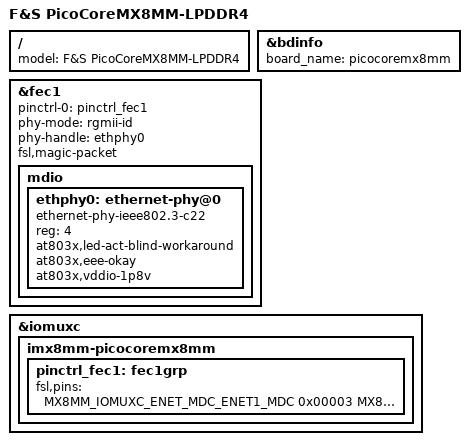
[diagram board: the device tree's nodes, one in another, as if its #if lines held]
/*
 * Copyright (C) 2019 F&S Elektronik Systeme GmbH
 *
 * This program is free software; you can redistribute it and/or modify
 * it under the terms of the GNU General Public License version 2 as
 * published by the Free Software Foundation.
 */

/dts-v1/;

/* Set board revision as 3-digit number, e.g. 110 for board rev. 1.10 */
#define CONFIG_PICOCOREMX8MM_BOARD_REVISION	130
/* Set baseboard revision as 3-digit number, e.g. 110 for board rev. 1.10 */
#define CONFIG_PICOCOREBBDSI_BOARD_REVISION	130

/* Activate this if you want to use the Cortex-M4 core */
//#define SUPPORT_M4

/* Display device-trees enables MIPI DSI */
/* MIPI DSI */
//#define CONFIG_PICOCOREMX8MM_MIPI_DSI

/*### UBoot deactivates on of the two boot medium NAND/eMMC */
/* On-board NAND */
#define CONFIG_PICOCOREMX8MM_NAND

/* On-board eMMC */
#define CONFIG_PICOCOREMX8MM_EMMC

/* Network */
#define CONFIG_PICOCOREMX8MM_ETH

/* WLAN/BLUETOOTH; either WLAN-only or combined WLAN/Bluetooth chip */
#define CONFIG_PICOCOREMX8MM_WLAN

/* USB */
#define CONFIG_PICOCOREMX8MM_USB_OTG1
#define CONFIG_PICOCOREMX8MM_USB_HOST
#define CONFIG_PICOCOREMX8MM_USB_OTG1_USBC
/* USB Type-C ALERT signal is available on J2_77 on BBDSI baseboard since
   Revision 1.40. Otherwise use polling with ~100ms */
#define CONFIG_PICOCOREMX8MM_USB_OTG1_USBC_ALERT

/* PCIe */
#define CONFIG_PICOCOREMX8MM_PCIE

/* I2C */
#define CONFIG_PICOCOREMX8MM_I2C_A
#define CONFIG_PICOCOREMX8MM_I2C_B
#define CONFIG_PICOCOREMX8MM_I2C_C
#define CONFIG_PICOCOREMX8MM_I2C_D

/* PWM and backlight brightness */
#define CONFIG_PICOCOREMX8MM_PWM_A
#define CONFIG_PICOCOREMX8MM_BL_CTRL

/* UART_A - UART1 */
#define CONFIG_PICOCOREMX8MM_UART_A
#define CONFIG_PICOCOREMX8MM_UART_A_RTSCTS

/* UART_B - UART2 */
#define CONFIG_PICOCOREMX8MM_UART_B
#define CONFIG_PICOCOREMX8MM_UART_B_RTSCTS

/* UART_C - UART4 */
#define CONFIG_PICOCOREMX8MM_UART_C

/* UART_D - UART3 */
#define CONFIG_PICOCOREMX8MM_UART_D

#define CONFIG_PICOCOREMX8MM_SPI_A
#define CONFIG_PICOCOREMX8MM_SPI_A_CAN_CONVERTER
//### TODO: implement QSPI support
#define CONFIG_PICOCOREMX8MM_SPI_B


/* CAN-FD - optional */
//#define CONFIG_PICOCOREMX8MM_CAN_A

/* Audio */
#define CONFIG_PICOCOREMX8MM_SGTL5000_AUDIO
/* AUDIO_B is an example implementation and must be
 * modified.
 */
//#define CONFIG_PICOCOREMX8MM_AUDIO_B

/* Camera on parallel CSI interface */
//#define CONFIG_PICOCOREMX8MM_PARALLEL_CAMERA

/* Camera on serial MIPI CSI interface */
//#define CONFIG_PICOCOREMX8MM_SERIAL_CAMERA
/* Experimental implementation for Basler dart daA4200-30mci.
 * Define CONFIG_PICOCOREMX8MM_SERIAL_CAMERA must also be set.
 */
//#define CONFIG_PICOCOREMX8MM_CAMERA_BASLER_daA4200

/*
 * SD_A - External SD port with Card Detect (CD) and Write Protect (WP)
 * On picocoremx8mm SKIT: external port is Micro-SD card slot with CD but
 * without WP
 */
#define CONFIG_PICOCOREMX8MM_SD_A
#define CONFIG_PICOCOREMX8MM_SD_A_CD
//#define CONFIG_PICOCOREMX8MM_SD_A_WP
//#define CONFIG_PICOCOREMX8MM_SD_A_8_BIT

/*
 * SD_B - External SD port with Card Detect (CD) and Write Protect (WP)
 * only available if WLAN is not equipped.
 */
#define CONFIG_PICOCOREMX8MM_SD_B
#define CONFIG_PICOCOREMX8MM_SD_B_CD
#define CONFIG_PICOCOREMX8MM_SD_B_WP

/* Check for invalid CONFIG combinations */

/*
 * Exclude devices from Linux that are used by the Cortex-M4 FreeRTOS examples
 *
 * - UART_D: Debug Console for Cortex-M4
 * - I2C_A:  I2C Bus used in I2C examples
 * - I2C_D:  I2C Bus used by the Audio Codec in SAI examples
 * - SPI_B:  SPI_B is used for ECSPI examples
 * - SDMA1:  Gets removed at another Point, it is used by SPI_B and UART driver
 *           examples
 * - SPI_A:  SPI_A using SDMA1 but SDMA1 is excluded so also exclude SPI_A
 *
 * In addition the following pins are already predefined in FreeRTOS to be used
 * as arbitrary GPIOs. Please remove the comment of the appropriate line of
 * each device from which you use any signal in your own application.
 *
 * - AUDIO_3: GPT capture driver example uses one of its Pins
 */
#ifdef SUPPORT_M4
#undef CONFIG_PICOCOREMX8MM_UART_C
//#undef CONFIG_PICOCOREMX8MM_I2C_A
//#undef CONFIG_PICOCOREMX8MM_SPI_A
//#undef CONFIG_PICOCOREMX8MM_SPI_B
/* Only undef if using audio/sai examples */
//#undef CONFIG_PICOCOREMX8MM_I2C_D
//#undef CONFIG_PICOCOREMX8MM_SGTL5000_AUDIO
#endif

/* If WLAN is equipped, SD_B is not available */
#ifdef CONFIG_PICOCOREMX8MM_WLAN
#undef CONFIG_PICOCOREMX8MM_SD_B
#undef CONFIG_PICOCOREMX8MM_SD_B_CD
#undef CONFIG_PICOCOREMX8MM_SD_B_WP
#endif

/* Set different settings for corresponding revision */
#if CONFIG_PICOCOREMX8MM_BOARD_REVISION < 130
#undef CONFIG_PICOCOREMX8MM_CAN_A
#undef CONFIG_PICOCOREMX8MM_AUDIO_B
#endif

/* Set different settings for corresponding baseboard revision */
#if CONFIG_PICOCOREBBDSI_BOARD_REVISION >= 130
#undef CONFIG_PICOCOREMX8MM_SPI_A_CAN_CONVERTER
#else
#undef CONFIG_PICOCOREMX8MM_USB_OTG1_USBC
#endif

#if !defined(CONFIG_PICOCOREMX8MM_USB_OTG1_USB) \
    || (CONFIG_PICOCOREBBDSI_BOARD_REVISION < 140)
#undef CONFIG_PICOCOREMX8MM_USB_OTG1_USBC_ALERT
#endif


#include "picocoremx8mm.dtsi"

/ {
	model = "F&S PicoCoreMX8MM-LPDDR4";
};

&bdinfo{
	board_name = "picocoremx8mm";
};

#ifdef CONFIG_PICOCOREMX8MM_ETH
&fec1 {
	pinctrl-names = "default";
	pinctrl-0 = <&pinctrl_fec1>;
	phy-mode = "rgmii-id";
	phy-handle = <&ethphy0>;
	fsl,magic-packet;
	status = "okay";

	mdio {
		#address-cells = <1>;
		#size-cells = <0>;

		ethphy0: ethernet-phy@0 {
			compatible = "ethernet-phy-ieee802.3-c22";
			reg = <4>;
			at803x,led-act-blind-workaround;
			at803x,eee-okay;
			at803x,vddio-1p8v;
		};
	};
};

&iomuxc {
	imx8mm-picocoremx8mm {
		pinctrl_fec1: fec1grp {
			fsl,pins = <
				MX8MM_IOMUXC_ENET_MDC_ENET1_MDC		0x00003
				MX8MM_IOMUXC_ENET_MDIO_ENET1_MDIO	0x00003
				MX8MM_IOMUXC_ENET_TD3_ENET1_RGMII_TD3	0x0001f
				MX8MM_IOMUXC_ENET_TD2_ENET1_RGMII_TD2	0x0001f
				MX8MM_IOMUXC_ENET_TD1_ENET1_RGMII_TD1	0x0001f
				MX8MM_IOMUXC_ENET_TD0_ENET1_RGMII_TD0	0x0001f
				MX8MM_IOMUXC_ENET_RD3_ENET1_RGMII_RD3	0x00091
				MX8MM_IOMUXC_ENET_RD2_ENET1_RGMII_RD2	0x00091
				MX8MM_IOMUXC_ENET_RD1_ENET1_RGMII_RD1	0x00091
				MX8MM_IOMUXC_ENET_RD0_ENET1_RGMII_RD0	0x00091
				MX8MM_IOMUXC_ENET_TXC_ENET1_RGMII_TXC	0x0001f
				MX8MM_IOMUXC_ENET_RXC_ENET1_RGMII_RXC	0x00091
				MX8MM_IOMUXC_ENET_RX_CTL_ENET1_RGMII_RX_CTL	0x00091
				MX8MM_IOMUXC_ENET_TX_CTL_ENET1_RGMII_TX_CTL	0x0001f
				/* reset */
				MX8MM_IOMUXC_GPIO1_IO05_GPIO1_IO5	0x00019
				/* INTn */
				MX8MM_IOMUXC_GPIO1_IO04_GPIO1_IO4	0x00019
			>;
		};
	};
};
#endif
